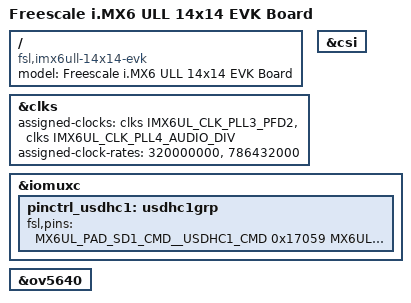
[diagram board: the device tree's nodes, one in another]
// SPDX-License-Identifier: (GPL-2.0 OR MIT)
//
// Copyright (C) 2016 Freescale Semiconductor, Inc.

/dts-v1/;

#include "imx6ull.dtsi"
#include "imx6ul-14x14-evk.dtsi"

/ {
	model = "Freescale i.MX6 ULL 14x14 EVK Board";
	compatible = "fsl,imx6ull-14x14-evk", "fsl,imx6ull";
};

&clks {
	assigned-clocks = <&clks IMX6UL_CLK_PLL3_PFD2>,
			  <&clks IMX6UL_CLK_PLL4_AUDIO_DIV>;
	assigned-clock-rates = <320000000>, <786432000>;
};

&csi {
	status = "okay";
};

&iomuxc {
	pinctrl_usdhc1: usdhc1grp {
		fsl,pins = <
			MX6UL_PAD_SD1_CMD__USDHC1_CMD     	0x17059
			MX6UL_PAD_SD1_CLK__USDHC1_CLK     	0x10071
			MX6UL_PAD_SD1_DATA0__USDHC1_DATA0 	0x17059
			MX6UL_PAD_SD1_DATA1__USDHC1_DATA1 	0x17059
			MX6UL_PAD_SD1_DATA2__USDHC1_DATA2 	0x17059
			MX6UL_PAD_SD1_DATA3__USDHC1_DATA3 	0x17059
			MX6UL_PAD_UART1_RTS_B__GPIO1_IO19       0x17059 /* SD1 CD */
			MX6UL_PAD_GPIO1_IO05__USDHC1_VSELECT    0x17059 /* SD1 VSELECT */
			MX6UL_PAD_GPIO1_IO09__GPIO1_IO09        0x17059 /* SD1 RESET */
		>;
	};
};

&ov5640 {
	status = "okay";
};

/delete-node/ &sim2;
